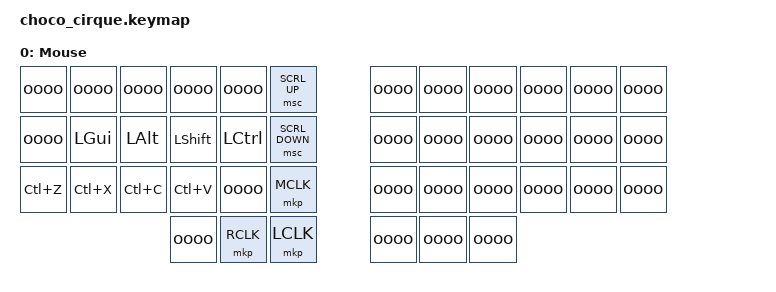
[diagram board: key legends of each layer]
#include <input/processors.dtsi>
#include <dt-bindings/zmk/pointing.h>
#include <dt-bindings/zmk/mouse.h>

#include "base.keymap"

// Functions for Cirque Trackpad
&glidepoint_listener {
    // Activating trackpad switches to MOUSE layer for 2000ms
    input-processors = <&zip_temp_layer	MOUSE 2000>;

    // When in the function layer, use trackpad for scrolling instead of pointer movement
    scroller {
        layers = <FUN>;
        input-processors = <&zip_xy_to_scroll_mapper>, <&zip_scroll_scaler 1 12>;
    };
};


/ {
    // Add Mouse layer to base-keymap
    keymap {
        compatible = "zmk,keymap";

        mouse_layer {
            bindings = <
            //╭──────────────┬──────────────┬─────────────┬─────────────┬─────────────┬─────────────╮   ╭─────────────┬─────────────┬─────────────┬─────────────┬─────────────┬─────────────╮
                oooo            oooo           oooo         oooo           oooo          &msc SCRL_UP       oooo        oooo          oooo          oooo          oooo           oooo
            //├──────────────┼──────────────┼─────────────┼─────────────┼─────────────┼─────────────┤   ├─────────────┼─────────────┼─────────────┼─────────────┼─────────────┼─────────────┤
                oooo            &kp LGUI        &kp LALT    &kp LSHFT      &kp LCTRL     &msc SCRL_DOWN     oooo        oooo          oooo          oooo          oooo           oooo
            //├──────────────┼──────────────┼─────────────┼─────────────┼─────────────┼─────────────┤   ├─────────────┼─────────────┼─────────────┼─────────────┼─────────────┼─────────────┤
                &kp LC(Z)       &kp LC(X)       &kp LC(C)   &kp LC(V)      oooo          &mkp MCLK          oooo        oooo          oooo          oooo          oooo           oooo
            //╰──────────────┴──────────────┴─────────────┼─────────────┼─────────────┼─────────────┤   ├─────────────┼─────────────┼─────────────┼─────────────┴─────────────┴─────────────╯
                                                            oooo           &mkp RCLK     &mkp LCLK          oooo        oooo          oooo
            //                                            ╰─────────────┴─────────────┴─────────────╯   ╰─────────────┴─────────────┴─────────────╯
            >;
            label = "Mouse";
        };


    };
};
